AUTOSAR XML (schema 4-3-1)
standard types defined: boolean, float64, uint16, uint8, boolean_CompuMethod, boolean_DataConstr, float64_DataConstr, uint16_DataConstr, uint8_DataConstr
package /ComponentTypes
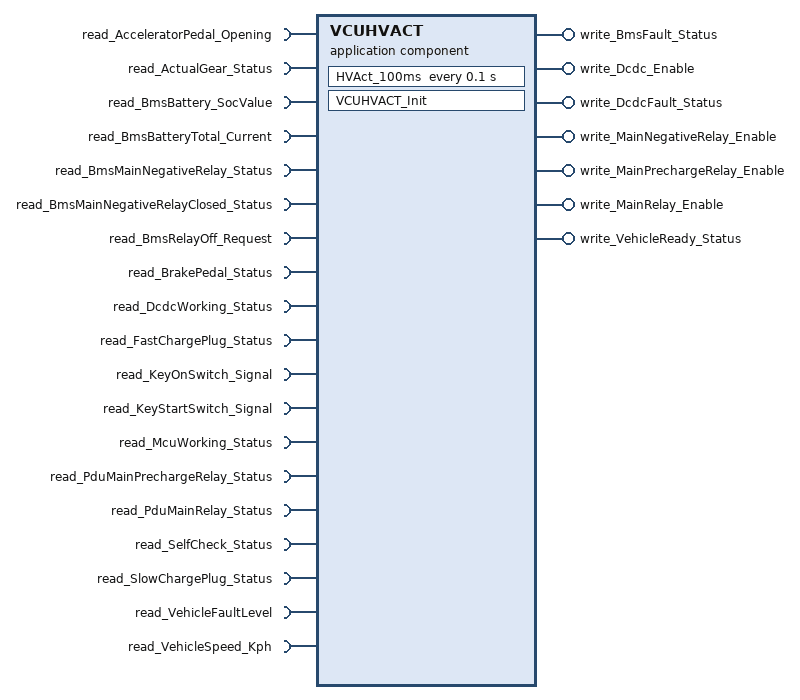
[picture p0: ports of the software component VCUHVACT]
  application sw component type VCUHVACT
    19 x require port:
      read_AcceleratorPedal_Opening: nonqueued-receiver-com-spec{data-element=uint16_t, init-value=ComSpec039facde_dfcb21f29e2de11d:0}, required-interface=read_AcceleratorPedal_Opening
      read_ActualGear_Status: nonqueued-receiver-com-spec{data-element=read_ActualGear_Status/uint8_t, init-value=ComSpec3b270652_ceb0d5259b16fe70:0}, required-interface=read_ActualGear_Status
      read_BmsBattery_SocValue: nonqueued-receiver-com-spec{data-element=read_BmsBattery_SocValue/float64, init-value=ComSpec95f45fb2_9487d10a407e7c55:0}, required-interface=read_BmsBattery_SocValue
      read_BmsBatteryTotal_Current: nonqueued-receiver-com-spec{data-element=read_BmsBatteryTotal_Current/float64, init-value=ComSpec5a641396_52aed583338215d3:0}, required-interface=read_BmsBatteryTotal_Current
      read_BmsMainNegativeRelay_Status: nonqueued-receiver-com-spec{data-element=read_BmsMainNegativeRelay_Status/bool, init-value=ComSpec7e8e28c8_1d62dabdf4608d4b:0}, required-interface=read_BmsMainNegativeRelay_Status
      read_BmsMainNegativeRelayClosed_Status: nonqueued-receiver-com-spec{data-element=read_BmsMainNegativeRelayClosed_Status/uint8_t, init-value=ComSpec9a14192c_2699edd58f2344a8:0}, required-interface=read_BmsMainNegativeRelayClosed_Status
      read_BmsRelayOff_Request: nonqueued-receiver-com-spec{data-element=read_BmsRelayOff_Request/uint8_t, init-value=ComSpec743f4812_43d6cbdc3626b853:0}, required-interface=read_BmsRelayOff_Request
      read_BrakePedal_Status: nonqueued-receiver-com-spec{data-element=read_BrakePedal_Status/uint8_t, init-value=ComSpecf8efda3b_6f3b35bb6fc02b78:0}, required-interface=read_BrakePedal_Status
      read_DcdcWorking_Status: nonqueued-receiver-com-spec{data-element=read_DcdcWorking_Status/uint8_t, init-value=ComSpec4077f57a_56893d5bf8537990:0}, required-interface=read_DcdcWorking_Status
      read_FastChargePlug_Status: nonqueued-receiver-com-spec{data-element=read_FastChargePlug_Status/bool, init-value=ComSpec230b1640_5fdcb1177e777134:0}, required-interface=read_FastChargePlug_Status
      read_KeyOnSwitch_Signal: nonqueued-receiver-com-spec{data-element=read_KeyOnSwitch_Signal/bool, init-value=ComSpecb7e9a279_316d3ac70ce67de3:0}, required-interface=read_KeyOnSwitch_Signal
      read_KeyStartSwitch_Signal: nonqueued-receiver-com-spec{data-element=read_KeyStartSwitch_Signal/bool, init-value=ComSpec50fcfb07_dfe4636be1ae07a0:0}, required-interface=read_KeyStartSwitch_Signal
      read_McuWorking_Status: nonqueued-receiver-com-spec{data-element=read_McuWorking_Status/uint8_t, init-value=ComSpecaf6e4f84_5e2c42122961e889:0}, required-interface=read_McuWorking_Status
      read_PduMainPrechargeRelay_Status: nonqueued-receiver-com-spec{data-element=read_PduMainPrechargeRelay_Status/uint8_t, init-value=ComSpec2f5c864c_86ef6498d86023c2:0}, required-interface=read_PduMainPrechargeRelay_Status
      read_PduMainRelay_Status: nonqueued-receiver-com-spec{data-element=read_PduMainRelay_Status/uint8_t, init-value=ComSpecd6044760_59346d0ba0d2c8b4:0}, required-interface=read_PduMainRelay_Status
      read_SelfCheck_Status: nonqueued-receiver-com-spec{data-element=read_SelfCheck_Status/bool, init-value=ComSpec92a2c703_3bedecc5b1d8f236:0}, required-interface=read_SelfCheck_Status
      read_SlowChargePlug_Status: nonqueued-receiver-com-spec{data-element=read_SlowChargePlug_Status/bool, init-value=ComSpec6cce201f_d5b012d2455e9382:0}, required-interface=read_SlowChargePlug_Status
      read_VehicleFaultLevel: nonqueued-receiver-com-spec{data-element=read_VehicleFaultLevel/uint8_t, init-value=ComSpecd895d622_7fe172f24a45dbd2:0}, required-interface=read_VehicleFaultLevel
      read_VehicleSpeed_Kph: nonqueued-receiver-com-spec{data-element=read_VehicleSpeed_Kph/float64, init-value=ComSpece3246d80_138b74ae1d105b63:0}, required-interface=read_VehicleSpeed_Kph
    7 x provide port:
      write_BmsFault_Status: nonqueued-sender-com-spec{data-element=write_BmsFault_Status/unit8_t, init-value=ComSpecac63c633_27f9a0764989967f:0}, provided-interface=write_BmsFault_Status
      write_Dcdc_Enable: nonqueued-sender-com-spec{data-element=write_Dcdc_Enable/uint8_t, init-value=ComSpeca530575b_103cc3ad6208a693:0}, provided-interface=write_Dcdc_Enable
      write_DcdcFault_Status: nonqueued-sender-com-spec{data-element=write_DcdcFault_Status/uint8_t, init-value=ComSpec8c367c3b_48ec50eba5ac990d:0}, provided-interface=write_DcdcFault_Status
      write_MainNegativeRelay_Enable: nonqueued-sender-com-spec{data-element=write_MainNegativeRelay_Enable/unit8_t, init-value=ComSpeca942b35d_0bc42d6cf1fd4342:0}, provided-interface=write_MainNegativeRelay_Enable
      write_MainPrechargeRelay_Enable: nonqueued-sender-com-spec{data-element=write_MainPrechargeRelay_Enable/uint8_t, init-value=ComSpec4b3c507b_f2582fc28d55e9da:0}, provided-interface=write_MainPrechargeRelay_Enable
      write_MainRelay_Enable: nonqueued-sender-com-spec{data-element=write_MainRelay_Enable/uint8_t, init-value=ComSpec4a64f9be_b31ca52ff449e72b:0}, provided-interface=write_MainRelay_Enable
      write_VehicleReady_Status: nonqueued-sender-com-spec{data-element=write_VehicleReady_Status/uint8_t, init-value=ComSpecd4afc4b6_8ec733c436962c4f:0}, provided-interface=write_VehicleReady_Status
    behavior VCUHVACT_InternalBehavior: handle-termination-and-restart=NO-SUPPORT
      timing event TMT_HVAct_100ms: start-on-event=HVAct_100ms, period=0.1
      runnable HVAct_100ms
        data-receive-point-by-arguments:
          16 x access:
            IN_read_AcceleratorPedal_Opening_uint16_t: accessed-variable=read_AcceleratorPedal_Opening.uint16_t
            IN_read_ActualGear_Status_uint8_t: accessed-variable=read_ActualGear_Status.uint8_t
            IN_read_BmsBattery_SocValue_float64: accessed-variable=read_BmsBattery_SocValue.float64
            IN_read_BmsMainNegativeRelayClosed_Status_uint8_t: accessed-variable=read_BmsMainNegativeRelayClosed_Status.uint8_t
            IN_read_BmsRelayOff_Request_uint8_t: accessed-variable=read_BmsRelayOff_Request.uint8_t
            IN_read_BrakePedal_Status_uint8_t: accessed-variable=read_BrakePedal_Status.uint8_t
            IN_read_DcdcWorking_Status_uint8_t: accessed-variable=read_DcdcWorking_Status.uint8_t
            IN_read_FastChargePlug_Status_bool: accessed-variable=read_FastChargePlug_Status.bool
            IN_read_KeyOnSwitch_Signal_bool: accessed-variable=read_KeyOnSwitch_Signal.bool
            IN_read_KeyStartSwitch_Signal_bool: accessed-variable=read_KeyStartSwitch_Signal.bool
            IN_read_McuWorking_Status_uint8_t: accessed-variable=read_McuWorking_Status.uint8_t
            IN_read_PduMainPrechargeRelay_Status_uint8_t: accessed-variable=read_PduMainPrechargeRelay_Status.uint8_t
            IN_read_PduMainRelay_Status_uint8_t: accessed-variable=read_PduMainRelay_Status.uint8_t
            IN_read_SlowChargePlug_Status_bool: accessed-variable=read_SlowChargePlug_Status.bool
            IN_read_VehicleFaultLevel_uint8_t: accessed-variable=read_VehicleFaultLevel.uint8_t
            IN_read_VehicleSpeed_Kph_float64: accessed-variable=read_VehicleSpeed_Kph.float64
        data-send-points:
          7 x access:
            OUT_write_BmsFault_Status_unit8_t: accessed-variable=write_BmsFault_Status.unit8_t
            OUT_write_Dcdc_Enable_uint8_t: accessed-variable=write_Dcdc_Enable.uint8_t
            OUT_write_DcdcFault_Status_uint8_t: accessed-variable=write_DcdcFault_Status.uint8_t
            OUT_write_MainNegativeRelay_Enable_unit8_t: accessed-variable=write_MainNegativeRelay_Enable.unit8_t
            OUT_write_MainPrechargeRelay_Enable_uint8_t: accessed-variable=write_MainPrechargeRelay_Enable.uint8_t
            OUT_write_MainRelay_Enable_uint8_t: accessed-variable=write_MainRelay_Enable.uint8_t
            OUT_write_VehicleReady_Status_uint8_t: accessed-variable=write_VehicleReady_Status.uint8_t
      runnable VCUHVACT_Init
package /PortInterfaces
  26 x sender receiver interface:
    read_AcceleratorPedal_Opening: invalidation-policy{data-element=uint16_t, handle-invalid=DONT-INVALIDATE}
      data uint16_t: category=VALUE, type=uint16
    read_ActualGear_Status: invalidation-policy{data-element=read_ActualGear_Status/uint8_t, handle-invalid=DONT-INVALIDATE}
      data uint8_t: category=VALUE, type=uint8
    read_BmsBattery_SocValue: invalidation-policy{data-element=read_BmsBattery_SocValue/float64, handle-invalid=DONT-INVALIDATE}
      data float64: category=VALUE, type=float64
    read_BmsBatteryTotal_Current: invalidation-policy{data-element=read_BmsBatteryTotal_Current/float64, handle-invalid=DONT-INVALIDATE}
      data float64: category=VALUE, type=float64
    read_BmsMainNegativeRelay_Status: invalidation-policy{data-element=read_BmsMainNegativeRelay_Status/bool, handle-invalid=DONT-INVALIDATE}
      data bool: category=VALUE, type=boolean
    read_BmsMainNegativeRelayClosed_Status: invalidation-policy{data-element=read_BmsMainNegativeRelayClosed_Status/uint8_t, handle-invalid=DONT-INVALIDATE}
      data uint8_t: category=VALUE, type=uint8
    read_BmsRelayOff_Request: invalidation-policy{data-element=read_BmsRelayOff_Request/uint8_t, handle-invalid=DONT-INVALIDATE}
      data uint8_t: category=VALUE, type=uint8
    read_BrakePedal_Status: invalidation-policy{data-element=read_BrakePedal_Status/uint8_t, handle-invalid=DONT-INVALIDATE}
      data uint8_t: category=VALUE, type=uint8
    read_DcdcWorking_Status: invalidation-policy{data-element=read_DcdcWorking_Status/uint8_t, handle-invalid=DONT-INVALIDATE}
      data uint8_t: category=VALUE, type=uint8
    read_FastChargePlug_Status: invalidation-policy{data-element=read_FastChargePlug_Status/bool, handle-invalid=DONT-INVALIDATE}
      data bool: category=VALUE, type=boolean
    read_KeyOnSwitch_Signal: invalidation-policy{data-element=read_KeyOnSwitch_Signal/bool, handle-invalid=DONT-INVALIDATE}
      data bool: category=VALUE, type=boolean
    read_KeyStartSwitch_Signal: invalidation-policy{data-element=read_KeyStartSwitch_Signal/bool, handle-invalid=DONT-INVALIDATE}
      data bool: category=VALUE, type=boolean
    read_McuWorking_Status: invalidation-policy{data-element=read_McuWorking_Status/uint8_t, handle-invalid=DONT-INVALIDATE}
      data uint8_t: category=VALUE, type=uint8
    read_PduMainPrechargeRelay_Status: invalidation-policy{data-element=read_PduMainPrechargeRelay_Status/uint8_t, handle-invalid=DONT-INVALIDATE}
      data uint8_t: category=VALUE, type=uint8
    read_PduMainRelay_Status: invalidation-policy{data-element=read_PduMainRelay_Status/uint8_t, handle-invalid=DONT-INVALIDATE}
      data uint8_t: category=VALUE, type=uint8
    read_SelfCheck_Status: invalidation-policy{data-element=read_SelfCheck_Status/bool, handle-invalid=DONT-INVALIDATE}
      data bool: category=VALUE, type=boolean
    read_SlowChargePlug_Status: invalidation-policy{data-element=read_SlowChargePlug_Status/bool, handle-invalid=DONT-INVALIDATE}
      data bool: category=VALUE, type=boolean
    read_VehicleFaultLevel: invalidation-policy{data-element=read_VehicleFaultLevel/uint8_t, handle-invalid=DONT-INVALIDATE}
      data uint8_t: category=VALUE, type=uint8
    read_VehicleSpeed_Kph: invalidation-policy{data-element=read_VehicleSpeed_Kph/float64, handle-invalid=DONT-INVALIDATE}
      data float64: category=VALUE, type=float64
    write_BmsFault_Status: invalidation-policy{data-element=write_BmsFault_Status/unit8_t, handle-invalid=DONT-INVALIDATE}
      data unit8_t: category=VALUE, type=uint8
    write_Dcdc_Enable: invalidation-policy{data-element=write_Dcdc_Enable/uint8_t, handle-invalid=DONT-INVALIDATE}
      data uint8_t: category=VALUE, type=uint8
    write_DcdcFault_Status: invalidation-policy{data-element=write_DcdcFault_Status/uint8_t, handle-invalid=DONT-INVALIDATE}
      data uint8_t: category=VALUE, type=uint8
    write_MainNegativeRelay_Enable: invalidation-policy{data-element=write_MainNegativeRelay_Enable/unit8_t, handle-invalid=DONT-INVALIDATE}
      data unit8_t: category=VALUE, type=uint8
    write_MainPrechargeRelay_Enable: invalidation-policy{data-element=write_MainPrechargeRelay_Enable/uint8_t, handle-invalid=DONT-INVALIDATE}
      data uint8_t: category=VALUE, type=uint8
    write_MainRelay_Enable: invalidation-policy{data-element=write_MainRelay_Enable/uint8_t, handle-invalid=DONT-INVALIDATE}
      data uint8_t: category=VALUE, type=uint8
    write_VehicleReady_Status: invalidation-policy{data-element=write_VehicleReady_Status/uint8_t, handle-invalid=DONT-INVALIDATE}
      data uint8_t: category=VALUE, type=uint8
